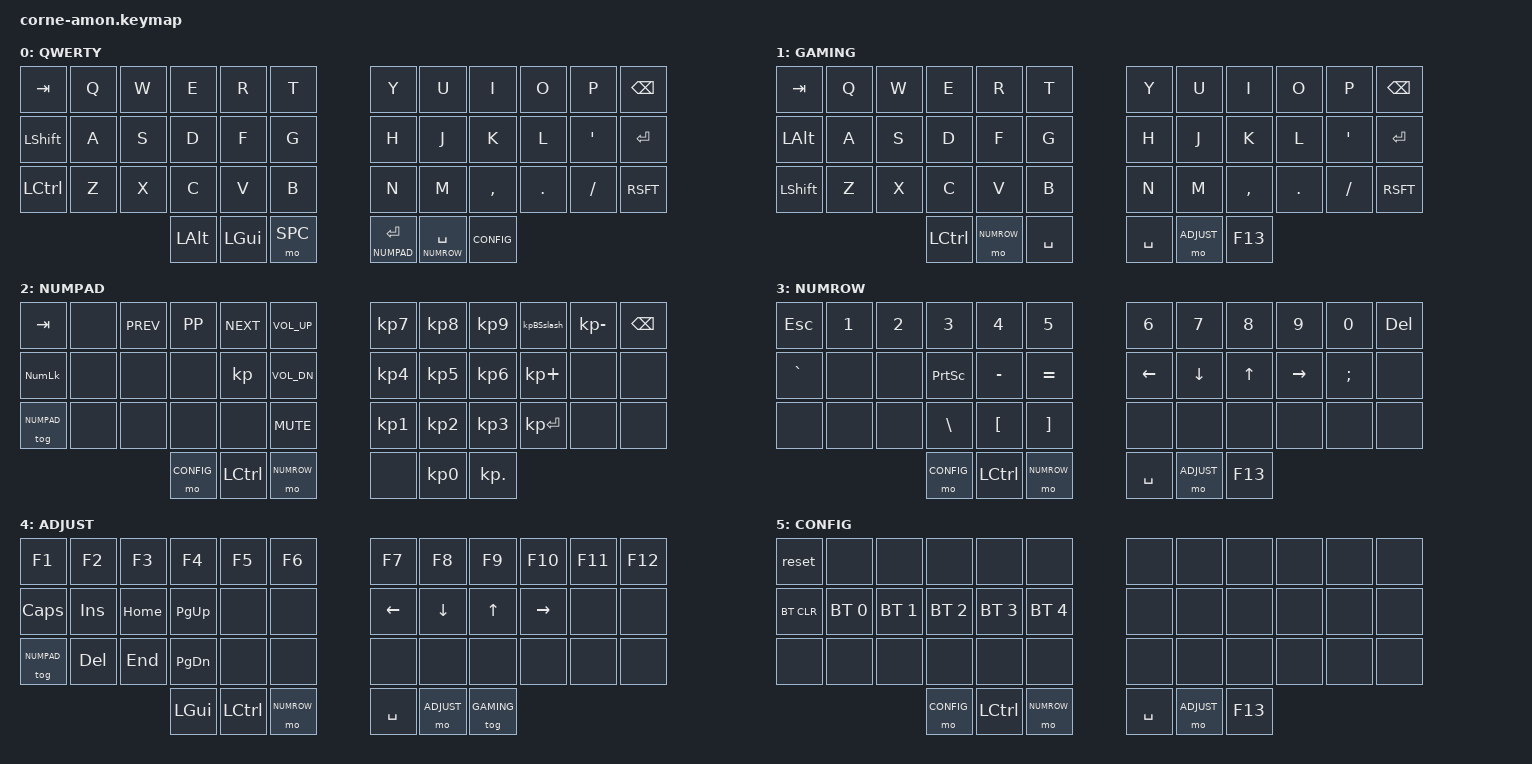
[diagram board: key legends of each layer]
/*
*
* Copyright (c) 2021 lowprokb.ca
* SPDX-License-Identifier: MIT
*
*/

#include <behaviors.dtsi>
#include <dt-bindings/zmk/keys.h>
#include <dt-bindings/zmk/bt.h>

#define QWERTY 0
#define GAMING 1
#define NUMPAD 2
#define NUMROW 3
#define ADJUST 4
#define CONFIG 5

/ {
        keymap {
                compatible = "zmk,keymap";

                default_layer {
                        label = "QWERTY";

// -----------------------------------------------------------------------------------------
// |  TAB |  Q  |  W  |  E  |  R  |  T  |   |  Y  |  U   |  I  |  O  |  P  | BKSP |
// | CTRL |  A  |  S  |  D  |  F  |  G  |   |  H  |  J   |  K  |  L  |  ;  |  '   |
// | SHFT |  Z  |  X  |  C  |  V  |  B  |   |  N  |  M   |  ,  |  .  |  /  | ESC  |
//                    | GUI | LWR | SPC |   | nument | arrowSPC  | ALT |
                        bindings = <
   &kp TAB     &kp Q  &kp W &kp E &kp R &kp T    &kp Y &kp U &kp I    &kp O   &kp P    &kp BKSP
   &kp LSHIFT  &kp A  &kp S &kp D &kp F &kp G    &kp H &kp J &kp K    &kp L   &kp QUOT &kp ENTER
   &kp LCTL    &kp Z  &kp X &kp C &kp V &kp B    &kp N &kp M &kp CMMA &kp DOT &kp FSLH &kp RSFT
              &kp LALT &kp LGUI &mo SPC          &mt NUMPAD ENTER &mt NUMROW SPC  &kp CONFIG
                        >;
                };

                gaming_layer {
                        label = "GAMING";
                        bindings = <
   &kp TAB   &kp Q &kp W &kp E &kp R &kp T    &kp Y &kp U &kp I    &kp O   &kp P    &kp BKSP
   &kp LALT  &kp A &kp S &kp D &kp F &kp G    &kp H &kp J &kp K    &kp L   &kp QUOT &kp ENTER
   &kp LSHFT &kp Z &kp X &kp C &kp V &kp B    &kp N &kp M &kp CMMA &kp DOT &kp FSLH &kp RSFT
               &kp LCTL &mo NUMROW &kp SPC    &kp SPC &mo ADJUST &kp F13
                        >;
                };

                numpad_layer {
                        label = "NUMPAD";
                        bindings = < 
// -----------------------------------------------------------------------------------------
// | TAB  |  _  |  PREV  |  PLAY  |  NEXT  |  VolUP  |   |  7  |  8   |  9  |  \  |  P  | BKSP |
// | NLOK |  _  |  _  |  _  |  _  |  VOLDN  |   |  4  |  5   |  6 |  L  |  ;  |  '   |
// | SHFT |  —  |  —  |  _  |  _  |  MUTE  |   |  1  |  2   |  3  |  .  |  /  | ESC  |
//                    | GUI | LWR | SPC |   | nument | arrowSPC  | ALT |

   &kp TAB &none &kp K_PREV &kp K_PP &kp K_NEXT &kp K_VOL_UP &kp KP_N7  &kp KP_N8 &kp KP_N9 &kp KP_BSslash &kp KP_MINUS &kp BSPC
   &kp KP_NLCK &none &none &none &kp  &kp K_VOL_DN   &kp KP_N4  &kp KP_N5 &kp KP_N6 &kp KP_PLUS    &none        &none
   &tog NUMPAD &none &none &none &none &kp K_MUTE     &kp KP_N1  &kp KP_N2 &kp KP_N3 &kp KP_ENTER   &none        &none
              &mo CONFIG &kp LCTL &mo NUMROW    &none &kp KP_N0 &kp KP_DOT
                        >;
                };

                numrow_layer {
                        label = "NUMROW";
                        bindings = <
   &kp ESC   &kp N1 &kp N2 &kp N3    &kp N4    &kp N5       &kp N6   &kp N7   &kp N8 &kp N9    &kp N0   &kp DEL
   &kp GRAVE &none  &none  &kp PSCRN &kp MINUS &kp EQUAL    &kp LEFT &kp DOWN &kp UP &kp RIGHT &kp SEMI &none
   &none     &none  &none  &kp BSLH  &kp LBKT  &kp RBKT     &none    &none    &none  &none     &none    &none 
                          &mo CONFIG &kp LCTL &mo NUMROW    &kp SPC &mo ADJUST &kp F13
                        >;
                };

                adjust_layer {
                        label = "ADJUST";
                        bindings = <
   &kp F1      &kp F2  &kp F3   &kp F4    &kp F5 &kp F6    &kp F7   &kp F8   &kp F9 &kp F10   &kp F11 &kp F12
   &kp CAPS    &kp INS &kp HOME &kp PG_UP &none  &none     &kp LEFT &kp DOWN &kp UP &kp RIGHT &none   &none
   &tog NUMPAD &kp DEL &kp END  &kp PG_DN &none  &none     &none    &none    &none  &none     &none   &none
                           &kp LGUI &kp LCTL &mo NUMROW    &kp SPC &mo ADJUST &tog GAMING
                        >;
                };

                config_layer {
                        label = "CONFIG";
                        bindings = <
   &reset     &none        &none        &none        &none        &none           &none &none &none &none &none &none 
   &bt BT_CLR &bt BT_SEL 0 &bt BT_SEL 1 &bt BT_SEL 2 &bt BT_SEL 3 &bt BT_SEL 4    &none &none &none &none &none &none
   &none      &none        &none        &none        &none        &none           &none &none &none &none &none &none
                                                &mo CONFIG &kp LCTL &mo NUMROW    &kp SPC &mo ADJUST &kp F13
                        >;
                };
        };
};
